# NANO100BN_v1 register map
File version: 1.0
Registers are 32-bit, read-write, reset 0x0 unless marked. A register's access mark holds for its fields unless they carry their own. Offsets are from the block's base; [hi:lo] are bit positions.

## PDMA_CH3 — PDMA Register Map
Base 0x50008300
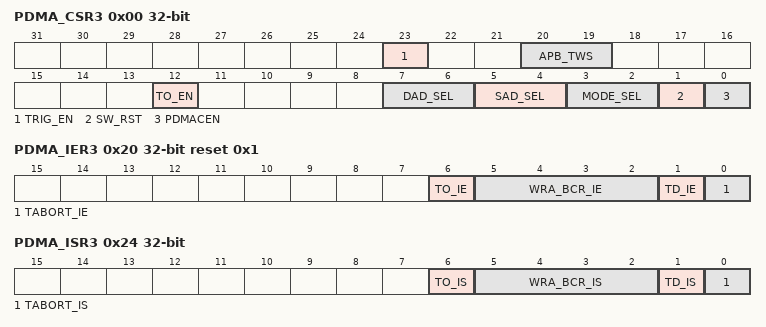
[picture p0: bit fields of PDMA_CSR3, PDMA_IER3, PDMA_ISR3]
0x00 PDMA_CSR3 — PDMA Control Register
  [23] TRIG_EN — TRIG_EN. Note1: When PDMA transfer completed, this bit will be cleared automatically. Note2: If the bus error occurs, all PDMA transfer will be stopped. Software must reset all PDMA channel, and then trig again.
    0=No effect; 1=PDMA data read or write transfer Enabled
  [20:19] APB_TWS — Peripheral Transfer Width Selection
  [12] TO_EN — Time-out Enable. This bit will enable PDMA internal Timer. While Timer is counted to zero, the TO_IS will be set.
    0=PDMA internal Timer Disabled; 1=PDMA internal Timer Enabled
  [7:6] DAD_SEL — Transfer Destination Address Direction Selection
  [5:4] SAD_SEL — Transfer Source Address Direction Selection
  [3:2] MODE_SEL — PDMA Mode Select
  [1] SW_RST — Software Engine Reset
    0=No effect; 1=Reset the internal state machine and pointers. The contents of control register will not be cleared. This bit will be auto cleared after few clock cycles
  [0] PDMACEN — PDMA Channel Enable. Setting this bit to "1" enables PDMA's operation. If this bit is cleared, PDMA will ignore all PDMA request and force Bus Master into IDLE state. Note: SW_RST will clear this bit.
0x04 PDMA_SAR3 — PDMA Source Address Register
  [31:0] PDMA_SAR — PDMA Transfer Source Address Register. This field indicates a 32-bit source address of PDMA. Note: The source address must be word alignment.
0x08 PDMA_DAR3 — PDMA Destination Address Register
  [31:0] PDMA_DAR — PDMA Transfer Destination Address Register. This field indicates a 32-bit destination address of PDMA. Note : The destination address must be word alignment
0x0C PDMA_BCR3 — PDMA Transfer Byte Count Register
  [15:0] PDMA_BCR — PDMA Transfer Byte Count Register. This field indicates a 16-bit transfer byte count of PDMA.
0x14 PDMA_CSAR3 ro — PDMA Current Source Address Register
  [31:0] PDMA_CSAR — PDMA Current Source Address Register (Read Only). This field indicates the source address where the PDMA transfer is just occurring.
0x18 PDMA_CDAR3 ro — PDMA Current Destination Address Register
  [31:0] PDMA_CDAR — PDMA Current Destination Address Register (Read Only). This field indicates the destination address where the PDMA transfer is just occurring.
0x1C PDMA_CBCR3 ro — PDMA Current Transfer Byte Count Register
  [23:0] PDMA_CBCR — PDMA Current Byte Count Register (Read Only). This field indicates the current remained byte count of PDMA. Note: These fields will be changed when PDMA finish data transfer (data transfer to destination address),
0x20 PDMA_IER3 reset 0x1 — PDMA Interrupt Enable Register
  [6] TO_IE — Time-Out Interrupt Enable
    0=Time-out interrupt Disabled; 1=Time-out interrupt Enabled
  [5:2] WRA_BCR_IE — Wrap Around Byte Count Interrupt Enable
  [1] TD_IE — PDMA Transfer Done Interrupt Enable
    0=Interrupt generator Disabled when PDMA transfer is done; 1=Interrupt generator Enabled when PDMA transfer is done
  [0] TABORT_IE — PDMA Read/Write Target Abort Interrupt Enable
    0=Target abort interrupt generation Disabled during PDMA transfer; 1=Target abort interrupt generation Enabled during PDMA transfer
0x24 PDMA_ISR3 — PDMA Interrupt Status Register
  [6] TO_IS — Time-Out Interrupt Status Flag. This flag indicated that PDMA has waited peripheral request for a period defined by PDMA_TCR. Note: This bit is cleared by writing "1" to itself.
    0=No time-out flag; 1=Time-out flag
  [5:2] WRA_BCR_IS — Wrap Around Transfer Byte Count Interrupt Status Flag
  [1] TD_IS — Transfer Done Interrupt Status Flag. This bit indicates that PDMA has finished all transfer. Note: This bit is cleared by writing "1" to itself.
    0=Not finished yet; 1=Done
  [0] TABORT_IS — PDMA Read/Write Target Abort Interrupt Status Flag. Note1: This bit is cleared by writing "1" to itself. Note2: The PDMA_ISR [TABORT_IF] indicate bus master received ERROR response or not, if bus master received occur it means that target abort is happened. PDMA controller will stop transfer and respond this event to software then go to IDLE state. When target abort occurred, software must reset PDMA controller, and then transfer those data again.
    0=No bus ERROR response received; 1=Bus ERROR response received
0x28 PDMA_TCR3 — PDMA Timer Counter Setting Register
  [15:0] PDMA_TCR — PDMA Timer Count Setting Register. Each PDMA controller contains an internal counter. The internal counter starts counting when setting PDMA_CSRx [TO_EN] register, clearing and restart counting when complete each peripheral request service.
0x80 PDMA_BUF3 ro — PDMA Internal Buffer FIFO
  [31:0] PDMA_BUF — PDMA Internal Buffer FIFO (Read Only). Each channel has its own 1 words internal buffer.
